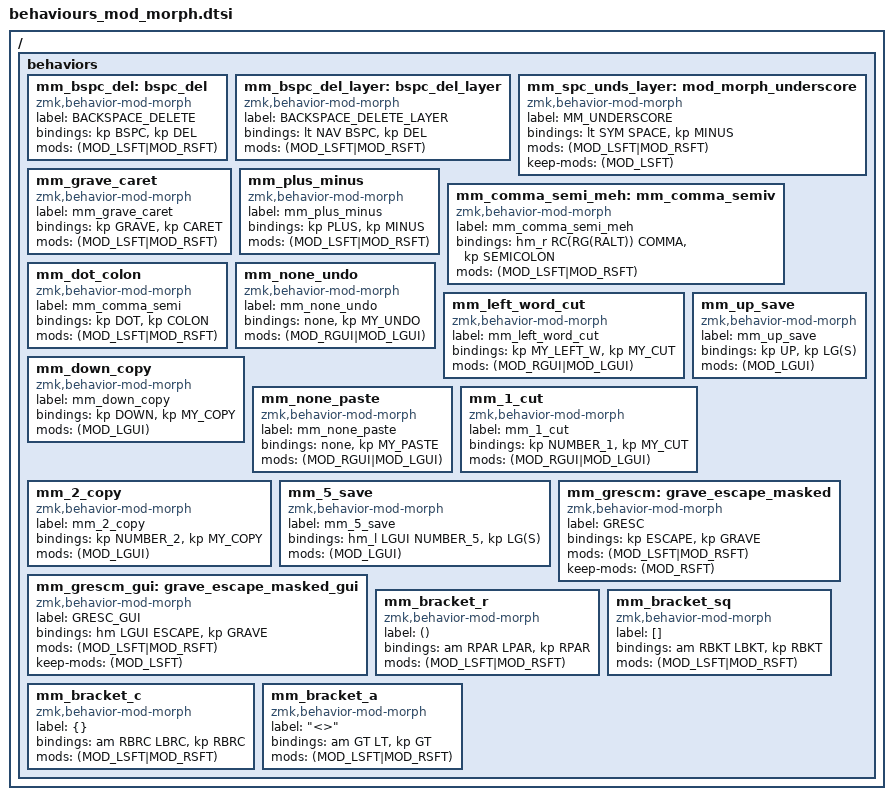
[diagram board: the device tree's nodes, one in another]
// Make sure settings.dtsi is included before this file

/ {

    behaviors {

        /*
         * Shifted Backspace deletes
         *
         * Usage: &mm_bspc_del
         * Tap: Backspace
         * Shift-Tap: Delete
         */
        mm_bspc_del: bspc_del {
            compatible = "zmk,behavior-mod-morph";
            label = "BACKSPACE_DELETE";
            #binding-cells = <0>;
            bindings = <&kp BSPC>, <&kp DEL>;
            mods = <(MOD_LSFT|MOD_RSFT)>;
        };

        /*
         * Shifted Backspace deletes + Layer Tap
         *
         * Usage: &mm_bspc_del_layer
         * Tap: Backspace
         * Shift-Tap: Delete
         * Hold: Switch layer
         */
        mm_bspc_del_layer: bspc_del_layer {
            compatible = "zmk,behavior-mod-morph";
            label = "BACKSPACE_DELETE_LAYER";
            #binding-cells = <0>;
            bindings = <&lt NAV BSPC>, <&kp DEL>;
            mods = <(MOD_LSFT|MOD_RSFT)>;
        };

        /*
         * Shifted Space underscores + Layer Tap
         *
         * Usage: &mm_spc_unds_layer
         * Tap: Space
         * LShift-Tap: -
         * RShift-Tap: _
         * Hold: Switch layer
         */
        mm_spc_unds_layer: mod_morph_underscore {
            compatible = "zmk,behavior-mod-morph";
            label = "MM_UNDERSCORE";
            #binding-cells = <0>;
            bindings = <&lt SYM SPACE>, <&kp MINUS>;
            mods = <(MOD_LSFT|MOD_RSFT)>;
            keep-mods = <(MOD_LSFT)>;
        };

        /*
         * Shifted grave types caret (^)
         *
         * Usage: &mm_grave_caret
         * Tap: `
         * Shift-Tap: ^
         */
        mm_grave_caret: mm_grave_caret {
            compatible = "zmk,behavior-mod-morph";
            label = "mm_grave_caret";
            #binding-cells = <0>;
            bindings = <&kp GRAVE>, <&kp CARET>;
            mods = <(MOD_LSFT|MOD_RSFT)>;
        };

        /*
         * Shifted plus types minus (-)
         *
         * Usage: &mm_plus_minus
         * Tap: `
         * Shift-Tap: ^
         */
        mm_plus_minus: mm_plus_minus {
            compatible = "zmk,behavior-mod-morph";
            label = "mm_plus_minus";
            #binding-cells = <0>;
            bindings = <&kp PLUS>, <&kp MINUS>;
            mods = <(MOD_LSFT|MOD_RSFT)>;
        };

        /*
         * Shifted comma types semicoln
         *
         * Usage: &mm_comma_semi
         * Tap: ,
         * Shift-Tap: ;
         * Hold: MEH
         */
        mm_comma_semi_meh: mm_comma_semiv {
            compatible = "zmk,behavior-mod-morph";
            label = "mm_comma_semi_meh";
            #binding-cells = <0>;
            bindings = <&hm_r RC(RG(RALT)) COMMA>, <&kp SEMICOLON>;
            mods = <(MOD_LSFT|MOD_RSFT)>;
        };

        /*
         * Shifted dot types colon
         *
         * Usage: &mm_dot_colon
         * Tap: .
         * Shift-Tap: :
         */
        mm_dot_colon: mm_dot_colon {
            compatible = "zmk,behavior-mod-morph";
            label = "mm_comma_semi";
            #binding-cells = <0>;
            bindings = <&kp DOT>, <&kp COLON>;
            mods = <(MOD_LSFT|MOD_RSFT)>;
        };


        /*********************************
         * Shortcuts on left layer - NAV *
         *********************************/


        /*
         * None and CMD+Z with CMD
         * Used on nav layer to allow both navigation as well as
         * cut, copy and paste
         *
         * Usage: &mm_none_undo
         * Tap: None
         * CMD-Tap: CMD+Z
         */
        mm_none_undo: mm_none_undo {
            compatible = "zmk,behavior-mod-morph";
            label = "mm_none_undo";
            #binding-cells = <0>;
            bindings = <&none>, <&kp MY_UNDO>;
            mods = <(MOD_RGUI|MOD_LGUI)>;
        };

        /*
         * Left Word and CMD+X with CMD
         * Used on nav layer to allow both navigation as well as
         * cut, copy and paste
         *
         * Usage: &mm_left_word_cut
         * Tap: Left Word
         * CMD-Tap: CMD+X
         */
        mm_left_word_cut: mm_left_word_cut {
            compatible = "zmk,behavior-mod-morph";
            label = "mm_left_word_cut";
            #binding-cells = <0>;
            bindings = <&kp MY_LEFT_W>, <&kp MY_CUT>;
            mods = <(MOD_RGUI|MOD_LGUI)>;
        };

        /*
         * Up and LCMD+S
         * Used on nav layer to allow both navigation as well as
         * cut, copy and paste.
         *
         * Usage: &mm_up_save
         * Tap: Up
         * LCMD-Tap: CMD+S
         * RCMD-Tap: CMD+Up
         */
        mm_up_save: mm_up_save {
            compatible = "zmk,behavior-mod-morph";
            label = "mm_up_save";
            #binding-cells = <0>;
            bindings = <&kp UP>, <&kp LG(S)>;
            mods = <(MOD_LGUI)>;
        };

        /*
         * Down and CMD/CTRL+C
         * Used on nav layer to allow both navigation as well as
         * cut, copy and paste
         *
         * Usage: &mm_down_copy
         * Tap: Down
         * LCMD: CMD+C
         * RCMD-Tap: CMD+Down
         */
        mm_down_copy: mm_down_copy {
            compatible = "zmk,behavior-mod-morph";
            label = "mm_down_copy";
            #binding-cells = <0>;
            bindings = <&kp DOWN>, <&kp MY_COPY>;
            mods = <(MOD_LGUI)>;
        };

        /*
         * None and CMD+V with CMD
         * Used on nav layer to allow both navigation as well as
         * cut, copy and paste
         *
         * Usage: &mm_none_copy
         * Tap: Nothing
         * CMD-Tap: CMD+V
         */
        mm_none_paste: mm_none_paste {
            compatible = "zmk,behavior-mod-morph";
            label = "mm_none_paste";
            #binding-cells = <0>;
            bindings = <&none>, <&kp MY_PASTE>;
            mods = <(MOD_RGUI|MOD_LGUI)>;
        };

        /*********************************
         * Shortcuts on left layer - NUM *
         *********************************/

        /*
         * 1 and CMD+X with CMD
         * Used on num layer to allow both navigation as well as
         * cut, copy and paste shortcuts.
         *
         * Usage: &mm_1_cut
         * Tap: 1
         * CMD-Tap: CMD+X
         */
        mm_1_cut: mm_1_cut {
            compatible = "zmk,behavior-mod-morph";
            label = "mm_1_cut";
            #binding-cells = <0>;
            bindings = <&kp NUMBER_1>, <&kp MY_CUT>;
            mods = <(MOD_RGUI|MOD_LGUI)>;
        };

        /*
         * Down and CMD/CTRL+C
         * Used on nav layer to allow both navigation as well as
         * cut, copy and paste shortcuts.
         *
         * Usage: &mm_2_copy
         * Tap: 2
         * LCMD: CMD+C
         * RCMD-Tap: CMD+2
         */
        mm_2_copy: mm_2_copy {
            compatible = "zmk,behavior-mod-morph";
            label = "mm_2_copy";
            #binding-cells = <0>;
            bindings = <&kp NUMBER_2>, <&kp MY_COPY>;
            mods = <(MOD_LGUI)>;
        };

        /*
         * 5 and LCMD+S
         * Used on num layer to allow both numbers as well as
         * cut, copy and paste shortcuts.
         *
         * Usage: &mm_5_save
         * Tap: 5
         * Hold: LGUI
         * LCMD-Tap: CMD+S
         * RCMD-Tap: CMD+5
         */
        mm_5_save: mm_5_save {
            compatible = "zmk,behavior-mod-morph";
            label = "mm_5_save";
            #binding-cells = <0>;
            bindings = <&hm_l LGUI NUMBER_5>, <&kp LG(S)>;
            mods = <(MOD_LGUI)>;
        };

        /*
         * Grave Escape
         *
         * Usage: &mm_spc_unds_layer
         * Tap: Escape
         * LShift-Tap: `
         * RShift-Tap: ~
         */
        mm_grescm: grave_escape_masked {
            compatible = "zmk,behavior-mod-morph";
            label = "GRESC";
            #binding-cells = <0>;
            bindings = <&kp ESCAPE>, <&kp GRAVE>;
            mods = <(MOD_LSFT|MOD_RSFT)>;
            keep-mods = <(MOD_RSFT)>;

        };

        /*
         * Grave Escape + GUI
         *
         * Usage: &grescm_gui
         * Tap: Escape
         * LShift-Tap: ~
         * RShift-Tap: `
         * Hold: GUI
         */
        mm_grescm_gui: grave_escape_masked_gui {
            compatible = "zmk,behavior-mod-morph";
            label = "GRESC_GUI";
            #binding-cells = <0>;
            bindings = <&hm LGUI ESCAPE>, <&kp GRAVE>;
            mods = <(MOD_LSFT|MOD_RSFT)>;
            keep-mods = <(MOD_LSFT)>;
        };

        /*
         * Round Bracket
         *
         * Usage: &mm_bracket_r
         * Tap: (
         * Shift-Tap: )
         * Hold: )
         */
        mm_bracket_r: mm_bracket_r {
            compatible = "zmk,behavior-mod-morph";
            label = "()";
            #binding-cells = <0>;
            bindings = <&am RPAR LPAR>, <&kp RPAR>;
            mods = <(MOD_LSFT|MOD_RSFT)>;
        };

        /*
         * Square Bracket
         *
         * Usage: &mm_bracket_sq
         * Tap: [
         * Shift-Tap: ]
         * Hold: ]
         */
        mm_bracket_sq: mm_bracket_sq {
            compatible = "zmk,behavior-mod-morph";
            label = "[]";
            #binding-cells = <0>;
            bindings = <&am RBKT LBKT>, <&kp RBKT>;
            mods = <(MOD_LSFT|MOD_RSFT)>;
        };

        /*
         * Curly Bracket
         *
         * Usage: &mm_bracket_c
         * Tap: {
         * Shift-Tap: }
         * Hold: }
         */
        mm_bracket_c: mm_bracket_c {
            compatible = "zmk,behavior-mod-morph";
            label = "{}";
            #binding-cells = <0>;
            bindings = <&am RBRC LBRC>, <&kp RBRC>;
            mods = <(MOD_LSFT|MOD_RSFT)>;
        };

        /*
         * Angled Bracket
         *
         * Usage: &mm_bracket_a
         * Tap: <
         * Shift-Tap: >
         * Hold: >
         */
        mm_bracket_a: mm_bracket_a {
            compatible = "zmk,behavior-mod-morph";
            label = "<>";
            #binding-cells = <0>;
            bindings = <&am GT LT>, <&kp GT>;
            mods = <(MOD_LSFT|MOD_RSFT)>;
        };
    };
};
